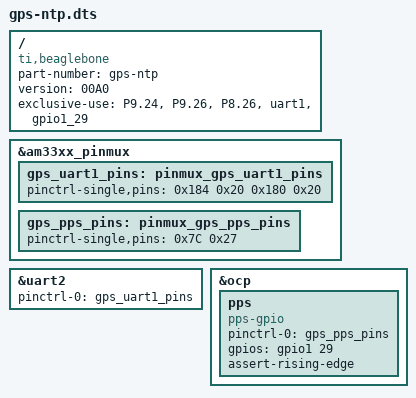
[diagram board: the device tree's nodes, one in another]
/*
 * Copyright (C) 2013 the8thlayerof.net
 * Modified by Matthew Iannucci in 2014 for use on UART1
 *
 * GPS cape for UART1 on connector pins P9.24 P9.26 P8.4
 *
 * This program is free software; you can redistribute it and/or modify
 * it under the terms of the GNU General Public License version 2 as
 * published by the Free Software Foundation.
 */
/dts-v1/;
/plugin/;

/ {
   	compatible = "ti,beaglebone", "ti,beaglebone-black";

        /* identification */
        part-number = "gps-ntp";
        version = "00A0";

        /* state the resources this cape uses */
        exclusive-use =
                /* the pin header uses */
                "P9.24",        /* uart1_rxd */
                "P9.26",        /* uart1_txd */
                "P8.26",         /* gpio1_7   */
                /* the hardware ip uses */
                "uart1",
                "gpio1_29";

        fragment@0 {
                target = <&am33xx_pinmux>;
                __overlay__ {
                        gps_uart1_pins: pinmux_gps_uart1_pins {
                                pinctrl-single,pins = <
                                        0x184 0x20 /* P9.26 uart1_rxd.uart4_rxd MODE6 INPUT (RX) */
                                        0x180 0x20 /* P9.24 uart1_txd.uart4_rxd MODE6 OUTPUT (TX) */
                                >;
                        };
                        
                        gps_pps_pins: pinmux_gps_pps_pins {
								pinctrl-single,pins = <
										0x7C 0x27 /* P8.4 gpio1_7 */
								>;
						};
										
                };
        };

		fragment@1 {
                target = <&uart2>;	/* really uart1 */
                __overlay__ {
                        status = "okay";
                        pinctrl-names = "default";
                        pinctrl-0 = <&gps_uart1_pins>;
                };
		};

		fragment@2 {
				target = <&ocp>;
				
                __overlay__ {
					pps {
						compatible = "pps-gpio";
                        status = "okay";
                        pinctrl-names = "default";
                        pinctrl-0 = <&gps_pps_pins>;
                        gpios = <&gpio1 29 0 >;
                        assert-rising-edge;
					};
				};
		};
};
